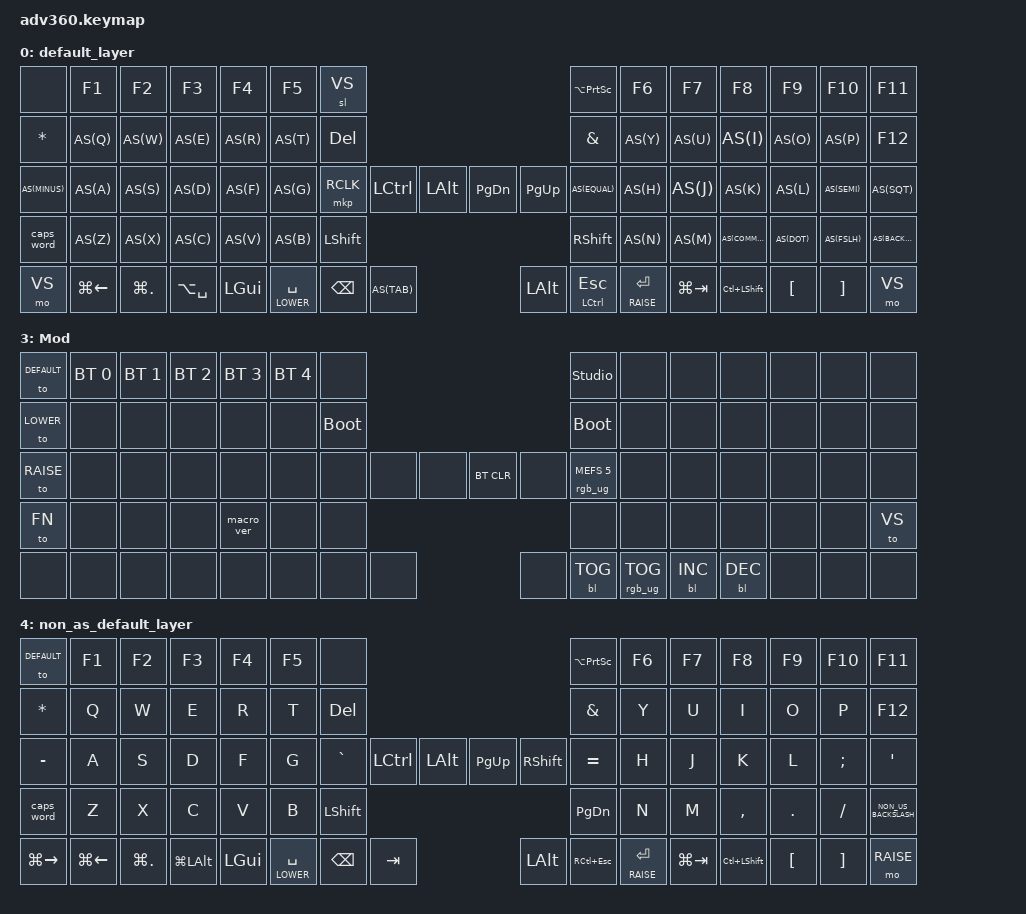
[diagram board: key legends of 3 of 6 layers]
#include <behaviors.dtsi>
#include <dt-bindings/zmk/keys.h>
#include <dt-bindings/zmk/bt.h>
#include <dt-bindings/zmk/rgb.h>
#include <dt-bindings/zmk/stp.h>
#include <dt-bindings/zmk/backlight.h>
#include <dt-bindings/zmk/pointing.h>
#include <dt-bindings/zmk/mouse.h>

#define AS(keycode) &as LS(keycode) keycode     // AutoShift Macro


#define DEFAULT 0
#define LOWER   1
#define RAISE   2
#define FN      2
#define MOD     3
#define VS      5
#define closeWindow &kp LC(F4)

&lt {
    tapping-term-ms = <200>;
};

&sl {
    release-after-ms = <20000>;
};

/ {

 macros {
         extract_method_macro: extract_method_macro {
            compatible = "zmk,behavior-macro";
            #binding-cells = <0>;
            wait-ms = <50>;
            tap-ms = <40>;
            bindings = <
                &macro_tap &kp LC(R)
                &macro_tap &kp LC(M)
            >;
        };

         comment_macro: comment_macro {
            compatible = "zmk,behavior-macro";
            #binding-cells = <0>;
            wait-ms = <50>;
            tap-ms = <40>;
            bindings = <
                &macro_tap &kp LC(K)
                &macro_tap &kp LC(C)
            >;
        };

          uncomment_macro: uncomment_macro {
            compatible = "zmk,behavior-macro";
            #binding-cells = <0>;
            wait-ms = <50>;
            tap-ms = <40>;
            bindings = <
                &macro_tap &kp LC(K)
                &macro_tap &kp LC(U)
            >;
        };
          
        nav_back_macro: nav_back_macro {
            compatible = "zmk,behavior-macro";
            #binding-cells = <0>;
            wait-ms = <40>;
            tap-ms = <30>;
            bindings = <
                &macro_tap &kp LC(MINUS)
            >;
        };

        nav_forward_macro: nav_forward_macro {
            compatible = "zmk,behavior-macro";
            #binding-cells = <0>;
            wait-ms = <50>;
            tap-ms = <30>;
            bindings = <
                &macro_tap &kp LC(LS(MINUS))
            >;
        };


        run_test_macro: run_test_macro {
            compatible = "zmk,behavior-macro";
            #binding-cells = <0>;
            wait-ms = <50>;
            tap-ms = <40>;
            bindings = <
                &macro_tap &kp LC(R)
                &macro_tap &kp LC(T)
            >;
        };

      
        debug_test_macro: debug_test_macro {
            compatible = "zmk,behavior-macro";
            #binding-cells = <0>;
            wait-ms = <50>;
            tap-ms = <40>;
            bindings = <
                &macro_tap &kp LC(R)
                &macro_tap &kp LC(D)
            >;
        };

        find_refs_macro: find_refs_macro {
            compatible = "zmk,behavior-macro";
            label = "Find All References";
            #binding-cells = <0>;
             bindings = <
                &mt LSHFT F12
            >;
        };

         rename_macro: rename_macro {
            compatible = "zmk,behavior-macro";
            #binding-cells = <0>;
            wait-ms = <50>;
            tap-ms = <40>;
            bindings = <
                &macro_tap &kp LC(R)
                &macro_tap &kp LC(R)
            >;
        };

    

            format_doc_macro: format_doc_macro {
    compatible = "zmk,behavior-macro";
    #binding-cells = <0>;
    wait-ms = <50>;
    tap-ms = <40>;
    bindings = <
        &macro_tap &kp LC(K)
        &macro_tap &kp LC(D)
    >;
    };

    };


    behaviors {
        #include "macros.dtsi"
        #include "version.dtsi"  
        



        hm: homerow_mods {
            compatible = "zmk,behavior-hold-tap";
            label = "HOMEROW_MODS";
            #binding-cells = <2>;
            tapping-term-ms = <200>;
            quick_tap_ms = <175>;
            flavor = "tap-preferred";
            bindings = <&kp>, <&kp>;
        };

        pht: positional_hold_tap {
            compatible = "zmk,behavior-hold-tap";
            #binding-cells = <2>;
            flavor = "hold-preferred";
            tapping-term-ms = <200>;
            quick_tap_ms = <160>;
            bindings = <&kp>, <&kp>;
            hold-trigger-key-positions = <1>; // W key position
        };

        as: auto_shift {
            compatible = "zmk,behavior-hold-tap";
            #binding-cells = <2>;
            tapping_term_ms = <167>;
            quick_tap_ms = <0>;
            flavor = "tap-preferred";
            bindings = <&kp>, <&kp>;
        };

     
     

    };

    keymap {
        compatible = "zmk,keymap";

        default_layer {
            bindings = <
                &none &kp F1     &kp F2     &kp F3     &kp F4     &kp F5     &sl VS                                                                                            &kp LA(PSCRN)   &kp F6     &kp F7     &kp F8     &kp F9     &kp F10    &kp F11
        
                &kp ASTRK       AS(Q)      AS(W)      AS(E)      AS(R)      AS(T)     &kp DEL                                                                                  &kp AMPS        AS(Y)      AS(U)      AS(I)      AS(O)      AS(P)     &kp F12
        
                AS(MINUS)       AS(A)      AS(S)      AS(D)      AS(F)      AS(G)     &mkp RCLK      &kp LCTRL   &kp LALT        &kp PG_DN  &kp PG_UP                         AS(EQUAL)        AS(H)      AS(J)      AS(K)      AS(L)      AS(SEMI)   AS(SQT)
        
                &caps_word      AS(Z)      AS(X)      AS(C)      AS(V)      AS(B)                                &kp LSHFT       &kp RSHFT                                                    AS(N)       AS(M)      AS(COMMA)  AS(DOT)    AS(FSLH)   AS(BACKSLASH)

                &mo VS  &kp LG(LEFT) &kp LG(DOT) &kp LA(SPACE) &kp LGUI             &lt LOWER SPACE   &kp BSPC   AS(TAB)         &kp LALT   &pht LCTRL ESC  &lt RAISE ENTER                   &kp LG(TAB)  &kp LC(LSHFT) &kp LBKT     &kp RBKT        &mo VS
            >;
        };

        keypad {
            display-name = "Kp";
            bindings = <
            &to DEFAULT   &kp N1     &kp N2   &kp N3   &none   &none   &none                                                                                                    &none         &none     &none    &none    &none   &kp KP_MULTIPLY &kp MINUS

                &to LOWER     &kp EXCL   &kp AT   &kp LBRC &kp RBRC &kp PIPE  &trans                                                                                           &kp AMPS       &none     &kp N7   &kp N8   &kp N9   &kp KP_MINUS   &kp BSLH

                &to RAISE     &kp HASH  &kp DOLLAR &kp LPAR &kp RPAR &kp GRAVE &trans                  &trans   &trans             &trans     &trans                           AS(EQUAL)          &none      &kp N4  &kp N5  &kp N6    &kp KP_PLUS     &kp SQT

                &to FN        &kp PRCNT &kp CARET &kp LBKT &kp RBKT &kp TILDE2                                  &trans             &trans                                                    &none       &kp N1    &kp N2  &kp N3   &kp ENTER      &none

                &to VS        &trans    &trans   &trans    &trans                                     &trans    &trans             &trans   &trans    &trans                                   &none    &kp N0      &kp KP_DOT    &none         &none
            >;
        };

        fn {
            display-name = "Fn";
            bindings = <
                &to DEFAULT &none &none &none &none &none &to MOD                                                                                                               &none       &none &none &none &none &none &none

                &to LOWER   &none &none &none &none &none &none                                                                                                                 &kp AMPS    &none &none &kp UP &none &none &none

                &to RAISE   &kp LGUI &kp LALT &kp LSHFT &kp LCTRL &none &none                        &trans      &trans              &trans &trans                              AS(EQUAL)   &kp HOME &kp LEFT &kp DOWN &kp RIGHT &kp END &none

                &to FN      &none &kp LC(X) &kp LC(C) &kp LC(V) &none                                            &trans              &trans                                                     &none &none &none &none &none

                &to VS      &none &none &none &none &trans                                  &trans      &trans &trans               &trans &trans                                       &none       &none &none &none &none
            >;
        };

        mod {
            display-name = "Mod";
            bindings = <
                &to DEFAULT &bt BT_SEL 0 &bt BT_SEL 1 &bt BT_SEL 2 &bt BT_SEL 3 &bt BT_SEL 4 &none
                &studio_unlock      &none &none &none &none &none &none

                &to LOWER   &none &none &none &none &none &bootloader
                &bootloader &none &none &none &none &none &none

                &to RAISE   &none &none &none &none &none &none
                &none       &none &bt BT_CLR &none &rgb_ug RGB_MEFS_CMD 5 &none
                &none       &none &none &none &none

                &to FN      &none &none &none &macro_ver &none
                &none       &none &none &none &none &none &none

                &to VS      &none &none &none &none &none &none
                &none       &none &none &bl BL_TOG &rgb_ug RGB_TOG
                &bl BL_INC  &bl BL_DEC &none &none &none
            >;
        };

        non_as_default_layer {
            bindings = <
                &to DEFAULT &kp F1 &kp F2 &kp F3 &kp F4 &kp F5 &none
                &kp LA(PSCRN) &kp F6 &kp F7 &kp F8 &kp F9 &kp F10 &kp F11

                &kp ASTRK &kp Q &kp W &kp E &kp R &kp T &kp DEL
                &kp AMPS  &kp Y &kp U &kp I &kp O &kp P &kp F12

                &kp MINUS &kp A &kp S &kp D &kp F &kp G &kp GRAVE
                &kp LCTRL &kp LALT &kp PG_UP &kp RSHFT &kp EQUAL &kp H &kp J
                &kp K &kp L &kp SEMI &kp SQT

                &caps_word &kp Z &kp X &kp C &kp V &kp B
                &kp LSHFT  &kp PG_DN
                &kp N &kp M &kp COMMA &kp DOT &kp FSLH &kp NON_US_BACKSLASH

                &kp LG(RIGHT) &kp LG(LEFT) &kp LG(DOT) &kp LG(LALT) &kp LGUI
                &lt LOWER SPACE &kp BSPC &kp TAB &kp LALT &kp RC(ESC)
                &lt RAISE ENTER &kp LG(TAB) &kp LC(LSHFT) &kp LBKT &kp RBKT &mo RAISE
            >;
        };

        vs {
            display-name = "VS";
            bindings = <
                &none          &kp F1      &kp F2      &kp F3      &kp F4               &run_test_macro &mo MOD                                                       &kp LA(PSCRN) &debug_test_macro &kp F7 &kp F8 &kp F9 &kp F10 &kp F11

                &kp LC(LA(F4)) closeWindow &kp LA(F12) &kp LC(F12) &extract_method_macro  &none          &none                                                        &kp AMPS      &find_refs_macro  AS(U)  AS(I) AS(O)   AS(P)   &kp F12

                &none          &none      &kp F12      &kp LC(F12) &none      &none &none                                        &none &none &none                    &none         AS(H) &nav_back_macro &nav_forward_macro AS(L) AS(SEMI) AS(SQT)

                &none &comment_macro &uncomment_macro  &none &format_doc_macro &none                                              &none &none                                        &kp N &none &none &none &none &none

                &none &none &none &none &none                                                                        &trans &none &none &none &trans &trans                           &none &none &none &none &none
            >;
        };
    };

    extra1 {
        display-name = "Red";
        status = "reserved";
    };

    extra2 {
        display-name = "Purple";
        status = "reserved";
    };

    extra3 {
        display-name = "Cyan";
        status = "reserved";
    };

    extra4 {
        display-name = "Yellow";
        status = "reserved";
    };
};
